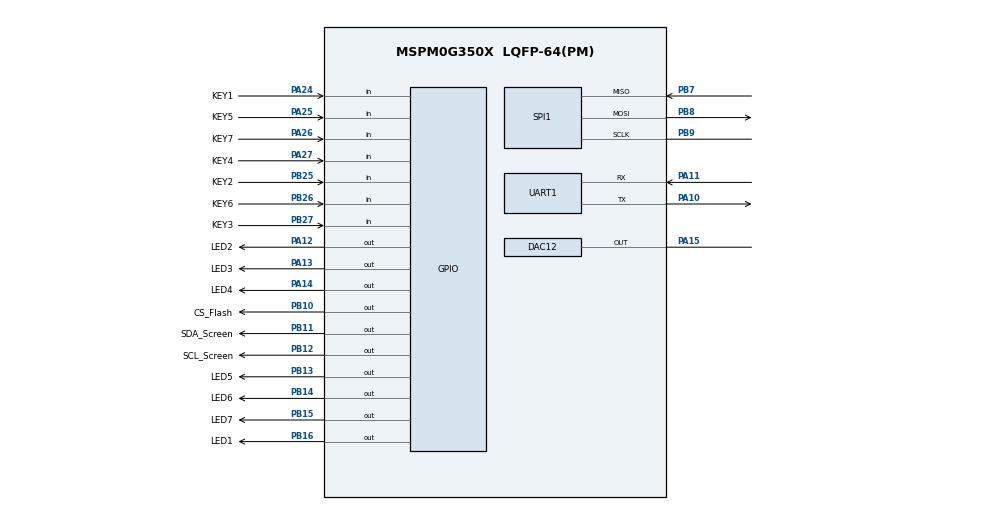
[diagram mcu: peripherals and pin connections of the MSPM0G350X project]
/**
 * @cliArgs --device "MSPM0G350X" --package "LQFP-64(PM)" --part "Default" --product "mspm0_sdk@1.20.01.06"
 * @versions {"tool":"1.18.1+3343"}
 */

/**
 * Import the modules used in this configuration.
 */
const DAC12  = scripting.addModule("/ti/driverlib/DAC12");
const GPIO   = scripting.addModule("/ti/driverlib/GPIO", {}, false);
const GPIO1  = GPIO.addInstance();
const GPIO2  = GPIO.addInstance();
const GPIO3  = GPIO.addInstance();
const SPI    = scripting.addModule("/ti/driverlib/SPI", {}, false);
const SPI1   = SPI.addInstance();
const SYSCTL = scripting.addModule("/ti/driverlib/SYSCTL");
const TIMER  = scripting.addModule("/ti/driverlib/TIMER", {}, false);
const TIMER1 = TIMER.addInstance();
const TIMER2 = TIMER.addInstance();
const UART   = scripting.addModule("/ti/driverlib/UART", {}, false);
const UART1  = UART.addInstance();

/**
 * Write custom configuration values to the imported modules.
 */
const gate8  = system.clockTree["MFPCLKGATE"];
gate8.enable = true;

DAC12.dacOutputPinEn            = true;
DAC12.dacConfigureDMA           = true;
DAC12.dacFIFOEn                 = true;
DAC12.dacFIFOThresh             = "TWO_QTRS_EMPTY";
DAC12.dacSampleTimerRate        = "1M";
DAC12.dacEnabledInterrupts      = ["DMA_DONE"];
DAC12.peripheral.$assign        = "DAC0";
DAC12.peripheral.OutPin.$assign = "PA15";
DAC12.OutPinConfig.$name        = "ti_driverlib_gpio_GPIOPinGeneric3";
DAC12.DMA_CHANNEL.$name         = "DMA_CH0";
DAC12.DMA_CHANNEL.addressMode   = "b2f";
DAC12.DMA_CHANNEL.srcLength     = "HALF_WORD";
DAC12.DMA_CHANNEL.dstLength     = "HALF_WORD";
DAC12.DMA_CHANNEL.srcIncrement  = "INCREMENT";

const Board = scripting.addModule("/ti/driverlib/Board", {}, false);

GPIO1.$name                         = "LEDs";
GPIO1.associatedPins.create(7);
GPIO1.associatedPins[0].$name       = "LED1";
GPIO1.associatedPins[0].pin.$assign = "PB16";
GPIO1.associatedPins[1].$name       = "LED2";
GPIO1.associatedPins[1].pin.$assign = "PA12";
GPIO1.associatedPins[2].$name       = "LED3";
GPIO1.associatedPins[2].pin.$assign = "PA13";
GPIO1.associatedPins[3].$name       = "LED4";
GPIO1.associatedPins[3].pin.$assign = "PA14";
GPIO1.associatedPins[4].$name       = "LED5";
GPIO1.associatedPins[4].pin.$assign = "PB13";
GPIO1.associatedPins[5].$name       = "LED6";
GPIO1.associatedPins[5].pin.$assign = "PB14";
GPIO1.associatedPins[6].$name       = "LED7";
GPIO1.associatedPins[6].pin.$assign = "PB15";

GPIO2.$name                         = "KEYs";
GPIO2.associatedPins.create(7);
GPIO2.associatedPins[0].$name       = "KEY1";
GPIO2.associatedPins[0].direction   = "INPUT";
GPIO2.associatedPins[0].pin.$assign = "PA24";
GPIO2.associatedPins[1].$name       = "KEY2";
GPIO2.associatedPins[1].direction   = "INPUT";
GPIO2.associatedPins[1].pin.$assign = "PB25";
GPIO2.associatedPins[2].$name       = "KEY3";
GPIO2.associatedPins[2].direction   = "INPUT";
GPIO2.associatedPins[2].pin.$assign = "PB27";
GPIO2.associatedPins[3].$name       = "KEY4";
GPIO2.associatedPins[3].direction   = "INPUT";
GPIO2.associatedPins[3].pin.$assign = "PA27";
GPIO2.associatedPins[4].$name       = "KEY5";
GPIO2.associatedPins[4].direction   = "INPUT";
GPIO2.associatedPins[4].pin.$assign = "PA25";
GPIO2.associatedPins[5].$name       = "KEY6";
GPIO2.associatedPins[5].direction   = "INPUT";
GPIO2.associatedPins[5].pin.$assign = "PB26";
GPIO2.associatedPins[6].$name       = "KEY7";
GPIO2.associatedPins[6].direction   = "INPUT";
GPIO2.associatedPins[6].pin.$assign = "PA26";

GPIO3.$name                         = "COMs";
GPIO3.associatedPins.create(3);
GPIO3.associatedPins[0].$name       = "CS_Flash";
GPIO3.associatedPins[0].pin.$assign = "PB10";
GPIO3.associatedPins[1].$name       = "SCL_Screen";
GPIO3.associatedPins[1].pin.$assign = "PB12";
GPIO3.associatedPins[2].$name       = "SDA_Screen";
GPIO3.associatedPins[2].pin.$assign = "PB11";

SPI1.frameFormat                        = "MOTO3";
SPI1.$name                              = "SPI_Flash";
SPI1.peripheral.$assign                 = "SPI1";
SPI1.peripheral.sclkPin.$assign         = "PB9";
SPI1.peripheral.mosiPin.$assign         = "PB8";
SPI1.peripheral.misoPin.$assign         = "PB7";
SPI1.sclkPinConfig.$name                = "ti_driverlib_gpio_GPIOPinGeneric0";
SPI1.sclkPinConfig.direction            = scripting.forceWrite("OUTPUT");
SPI1.sclkPinConfig.onlyInternalResistor = scripting.forceWrite(false);
SPI1.sclkPinConfig.passedPeripheralType = scripting.forceWrite("Digital");
SPI1.mosiPinConfig.$name                = "ti_driverlib_gpio_GPIOPinGeneric1";
SPI1.mosiPinConfig.direction            = scripting.forceWrite("OUTPUT");
SPI1.mosiPinConfig.hideOutputInversion  = scripting.forceWrite(false);
SPI1.mosiPinConfig.onlyInternalResistor = scripting.forceWrite(false);
SPI1.mosiPinConfig.passedPeripheralType = scripting.forceWrite("Digital");
SPI1.misoPinConfig.$name                = "ti_driverlib_gpio_GPIOPinGeneric2";
SPI1.misoPinConfig.onlyInternalResistor = scripting.forceWrite(false);
SPI1.misoPinConfig.passedPeripheralType = scripting.forceWrite("Digital");

SYSCTL.forceDefaultClkConfig = true;
SYSCTL.clockTreeEn           = true;

TIMER1.$name       = "TIMER_KEYs";
TIMER1.timerPeriod = "1ms";
TIMER1.timerClkSrc = "LFCLK";
TIMER1.interrupts  = ["ZERO"];
TIMER1.timerMode   = "PERIODIC";

TIMER2.$name       = "TIMER_LEDs";
TIMER2.timerClkSrc = "LFCLK";
TIMER2.interrupts  = ["ZERO"];
TIMER2.timerMode   = "PERIODIC";
TIMER2.timerPeriod = "2s";

UART1.$name                            = "UART_Debug";
UART1.targetBaudRate                   = 115200;
UART1.peripheral.$assign               = "UART0";
UART1.peripheral.rxPin.$assign         = "PA11";
UART1.peripheral.txPin.$assign         = "PA10";
UART1.txPinConfig.direction            = scripting.forceWrite("OUTPUT");
UART1.txPinConfig.hideOutputInversion  = scripting.forceWrite(false);
UART1.txPinConfig.onlyInternalResistor = scripting.forceWrite(false);
UART1.txPinConfig.passedPeripheralType = scripting.forceWrite("Digital");
UART1.txPinConfig.$name                = "ti_driverlib_gpio_GPIOPinGeneric8";
UART1.rxPinConfig.hideOutputInversion  = scripting.forceWrite(false);
UART1.rxPinConfig.onlyInternalResistor = scripting.forceWrite(false);
UART1.rxPinConfig.passedPeripheralType = scripting.forceWrite("Digital");
UART1.rxPinConfig.$name                = "ti_driverlib_gpio_GPIOPinGeneric9";

/**
 * Pinmux solution for unlocked pins/peripherals. This ensures that minor changes to the automatic solver in a future
 * version of the tool will not impact the pinmux you originally saw.  These lines can be completely deleted in order to
 * re-solve from scratch.
 */
DAC12.DMA_CHANNEL.peripheral.$suggestSolution = "DMA_CH0";
Board.peripheral.$suggestSolution             = "DEBUGSS";
Board.peripheral.swclkPin.$suggestSolution    = "PA20";
Board.peripheral.swdioPin.$suggestSolution    = "PA19";
TIMER1.peripheral.$suggestSolution            = "TIMA1";
TIMER2.peripheral.$suggestSolution            = "TIMA0";
